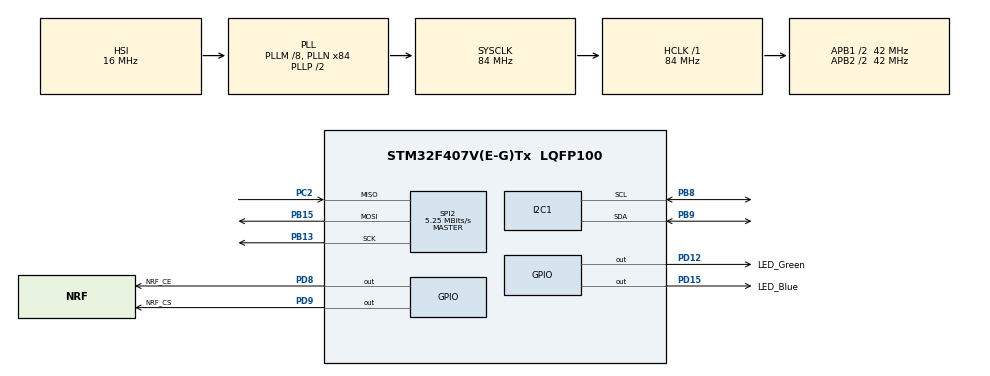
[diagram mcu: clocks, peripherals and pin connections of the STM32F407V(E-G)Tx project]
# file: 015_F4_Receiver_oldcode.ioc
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Mcu.Family=STM32F4
Mcu.Name=STM32F407V(E-G)Tx
Mcu.Package=LQFP100
NVIC.PriorityGroup=NVIC_PRIORITYGROUP_0
PB13.Mode=Full_Duplex_Master
PB13.Signal=SPI2_SCK
PB15.Mode=Full_Duplex_Master
PB15.Signal=SPI2_MOSI
PB8.Mode=I2C
PB8.Signal=I2C1_SCL
PB9.Mode=I2C
PB9.Signal=I2C1_SDA
PC2.Mode=Full_Duplex_Master
PC2.Signal=SPI2_MISO
PD12.GPIO_Label=LED_Green
PD12.GPIO_PuPd=GPIO_NOPULL
PD12.GPIO_Speed=GPIO_SPEED_FREQ_LOW
PD12.Signal=GPIO_Output
PD15.GPIO_Label=LED_Blue
PD15.GPIO_PuPd=GPIO_NOPULL
PD15.GPIO_Speed=GPIO_SPEED_FREQ_LOW
PD15.Signal=GPIO_Output
PD8.GPIO_Label=NRF_CE
PD8.Signal=GPIO_Output
PD9.GPIO_Label=NRF_CS
PD9.Signal=GPIO_Output
ProjectManager.HeapSize=0x200
ProjectManager.StackSize=0x400
ProjectManager.TargetToolchain=MDK-ARM V5.32
RCC.48MHZClocksFreq_Value=24000000
RCC.AHBFreq_Value=84000000
RCC.APB1CLKDivider=RCC_HCLK_DIV2
RCC.APB1Freq_Value=42000000
RCC.APB1TimFreq_Value=84000000
RCC.APB2CLKDivider=RCC_HCLK_DIV2
RCC.APB2Freq_Value=42000000
RCC.APB2TimFreq_Value=84000000
RCC.CortexFreq_Value=84000000
RCC.HCLKFreq_Value=84000000
RCC.HSE_VALUE=8000000
RCC.HSI_VALUE=16000000
RCC.LSE_VALUE=32768
RCC.PLLM=8
RCC.PLLN=84
RCC.PLLQ=7
RCC.SYSCLKFreq_VALUE=84000000
RCC.SYSCLKSource=RCC_SYSCLKSOURCE_PLLCLK
RCC.VCOOutputFreq_Value=168000000
SPI2.BaudRatePrescaler=SPI_BAUDRATEPRESCALER_8
SPI2.CalculateBaudRate=5.25 MBits/s
SPI2.Direction=SPI_DIRECTION_2LINES
SPI2.Mode=SPI_MODE_MASTER
SPI2.VirtualType=VM_MASTER
board=STM32F407G-DISC1

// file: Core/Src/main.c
/* USER CODE BEGIN Header */
/**
  ******************************************************************************
  * @file           : main.c
  * @brief          : Main program body
  ******************************************************************************
  * @attention
  *
  * <h2><center>&copy; Copyright (c) 2021 STMicroelectronics.
  * All rights reserved.</center></h2>
  *
  * This software component is licensed by ST under BSD 3-Clause license,
  * the "License"; You may not use this file except in compliance with the
  * License. You may obtain a copy of the License at:
  *                        opensource.org/licenses/BSD-3-Clause
  *
  ******************************************************************************
  */
/* USER CODE END Header */
#include "main.h"
#include "i2c.h"
#include "spi.h"
#include "gpio.h"

/* USER CODE BEGIN Includes */
#include "nrf24l01.h"
#include "ads1115.h"
#include "joystick.h"
//#include "string.h"

/* USER CODE END Includes */

void SystemClock_Config(void);

/* USER CODE BEGIN 0 */

uint8_t TxAddresses[]={0xEE,0xDD,0xCC,0xBB,0xAA}; // based on datasheet. It has to be same with RxAdress on Receiver side
	uint8_t TxData[2]; //same with transmitted data packet

/* USER CODE END 0 */

int main(void)
{

  /* MCU Configuration--------------------------------------------------------*/

  /* Reset of all peripherals, Initializes the Flash interface and the Systick. */
  HAL_Init();

  /* Configure the system clock */
  SystemClock_Config();

  /* Initialize all configured peripherals */
  MX_GPIO_Init();
  MX_SPI2_Init();
  MX_I2C1_Init();
  /* USER CODE BEGIN 2 */
	nrf24_Init();

	nrf24_TxMode(TxAddresses,10); //Set Nrf24L01 as Transceiver

  /* USER CODE END 2 */

  /* Infinite loop */
  while (1)
  {

    /* USER CODE BEGIN 3 */

		TxData[0] =(uint8_t) Read_Joystick_X(); //Axis X is first byte of TxData
		TxData[1] =(uint8_t) Read_Joystick_Y(); //Axis Y is second

		if(nrf24_Transmit(TxData))
		{
		//	HAL_GPIO_TogglePin(LED_Green_GPIO_Port,LED_Green_Pin); //We can see there is transmission through led
			//HAL_Delay(500); //wait for led's toggle
		}

		else
		{
			HAL_GPIO_WritePin(LED_Green_GPIO_Port,LED_Green_Pin,GPIO_PIN_SET); //if there is no transmission

		}

  }
  /* USER CODE END 3 */
}

void SystemClock_Config(void)
{
  RCC_OscInitTypeDef RCC_OscInitStruct = {0};
  RCC_ClkInitTypeDef RCC_ClkInitStruct = {0};

  /** Configure the main internal regulator output voltage
  */
  __HAL_RCC_PWR_CLK_ENABLE();
  __HAL_PWR_VOLTAGESCALING_CONFIG(PWR_REGULATOR_VOLTAGE_SCALE1);
  /** Initializes the RCC Oscillators according to the specified parameters
  * in the RCC_OscInitTypeDef structure.
  */
  RCC_OscInitStruct.OscillatorType = RCC_OSCILLATORTYPE_HSI;
  RCC_OscInitStruct.HSIState = RCC_HSI_ON;
  RCC_OscInitStruct.HSICalibrationValue = RCC_HSICALIBRATION_DEFAULT;
  RCC_OscInitStruct.PLL.PLLState = RCC_PLL_ON;
  RCC_OscInitStruct.PLL.PLLSource = RCC_PLLSOURCE_HSI;
  RCC_OscInitStruct.PLL.PLLM = 8;
  RCC_OscInitStruct.PLL.PLLN = 84;
  RCC_OscInitStruct.PLL.PLLP = RCC_PLLP_DIV2;
  RCC_OscInitStruct.PLL.PLLQ = 7;
  if (HAL_RCC_OscConfig(&RCC_OscInitStruct) != HAL_OK)
  {
    Error_Handler();
  }
  /** Initializes the CPU, AHB and APB buses clocks
  */
  RCC_ClkInitStruct.ClockType = RCC_CLOCKTYPE_HCLK|RCC_CLOCKTYPE_SYSCLK
                              |RCC_CLOCKTYPE_PCLK1|RCC_CLOCKTYPE_PCLK2;
  RCC_ClkInitStruct.SYSCLKSource = RCC_SYSCLKSOURCE_PLLCLK;
  RCC_ClkInitStruct.AHBCLKDivider = RCC_SYSCLK_DIV1;
  RCC_ClkInitStruct.APB1CLKDivider = RCC_HCLK_DIV2;
  RCC_ClkInitStruct.APB2CLKDivider = RCC_HCLK_DIV2;

  if (HAL_RCC_ClockConfig(&RCC_ClkInitStruct, FLASH_LATENCY_2) != HAL_OK)
  {
    Error_Handler();
  }
}

/* USER CODE BEGIN 4 */

void HAL_GPIO_EXTI_Callback(uint16_t GPIO_Pin)
{

}

/* USER CODE END 4 */

void Error_Handler(void)
{
  __disable_irq();
  while (1)
  {
  }
}

/************************ (C) COPYRIGHT STMicroelectronics *****END OF FILE****/
